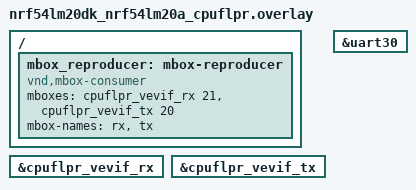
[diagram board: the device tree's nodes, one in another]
/*
 * Copyright 2026 Nordic Semiconductor ASA
 * SPDX-License-Identifier: LicenseRef-Nordic-5-Clause
 */

/ {
	mbox_reproducer: mbox-reproducer {
		compatible = "vnd,mbox-consumer";
		mboxes = <&cpuflpr_vevif_rx 21>, <&cpuflpr_vevif_tx 20>;
		mbox-names = "rx", "tx";
	};
};

&cpuflpr_vevif_rx {
	status = "okay";
};

&cpuflpr_vevif_tx {
	status = "okay";
};

&uart30 {
	/delete-property/ hw-flow-control;
};
